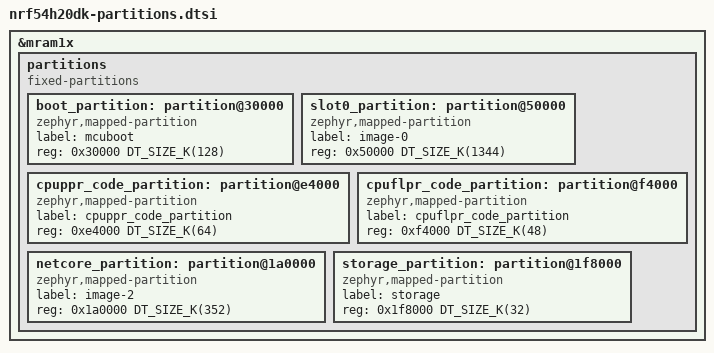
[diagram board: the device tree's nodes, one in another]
/* Partition layout for nrf54h20dk: the flash memory map shared by the
 * bootloader and every application image. Generated by
 * tools/partition_layout.py; do not edit by hand -- re-run
 * `python3 tools/partition_layout.py --fix nrf54h20dk` after changing
 * the upstream board geometry or tools/boards.toml.
 *
 * Board-specific overlay glue (delete-nodes, device enablement,
 * aliases/chosen) lives in dts/nordic/nrf54h20dk.dtsi, which includes
 * this file.
 */

&mram1x {
	partitions {
		compatible = "fixed-partitions";
		#address-cells = <1>;
		#size-cells = <1>;
		ranges;

		boot_partition: partition@30000 {
			compatible = "zephyr,mapped-partition";
			label = "mcuboot";
			reg = <0x30000 DT_SIZE_K(128)>;
		};

		slot0_partition: partition@50000 {
			compatible = "zephyr,mapped-partition";
			label = "image-0";
			reg = <0x50000 DT_SIZE_K(1344)>;
		};

		cpuppr_code_partition: partition@e4000 {
			compatible = "zephyr,mapped-partition";
			label = "cpuppr_code_partition";
			reg = <0xe4000 DT_SIZE_K(64)>;
		};

		cpuflpr_code_partition: partition@f4000 {
			compatible = "zephyr,mapped-partition";
			label = "cpuflpr_code_partition";
			reg = <0xf4000 DT_SIZE_K(48)>;
		};

		netcore_partition: partition@1a0000 {
			compatible = "zephyr,mapped-partition";
			label = "image-2";
			reg = <0x1a0000 DT_SIZE_K(352)>;
		};

		storage_partition: partition@1f8000 {
			compatible = "zephyr,mapped-partition";
			label = "storage";
			reg = <0x1f8000 DT_SIZE_K(32)>;
		};
	};
};
